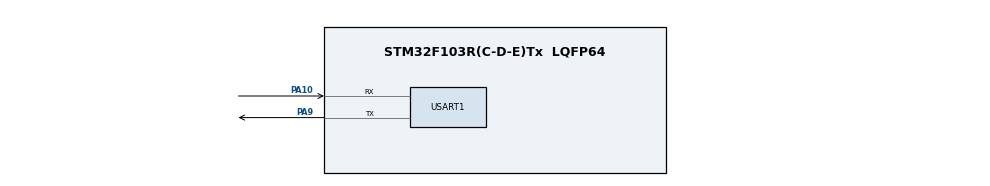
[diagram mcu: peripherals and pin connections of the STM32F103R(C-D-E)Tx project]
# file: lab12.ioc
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FREERTOS.Queues01=myQueue01,16,uint16_t,0,Dynamic,NULL,NULL
FREERTOS.Tasks01=MsgProducer,0,128,MsgProducerTask,Default,NULL,Dynamic,NULL,NULL;MsgConsumer,0,128,MsgConsumerTask,Default,NULL,Dynamic,NULL,NULL
Mcu.Family=STM32F1
Mcu.Name=STM32F103R(C-D-E)Tx
Mcu.Package=LQFP64
NVIC.PriorityGroup=NVIC_PRIORITYGROUP_4
NVIC.TIM3_IRQn=true\:0\:0\:false\:false\:true\:false\:false\:true
NVIC.TimeBase=TIM3_IRQn
NVIC.TimeBaseIP=TIM3
NVIC.USART1_IRQn=true\:0\:0\:false\:false\:true\:false\:true\:true
PA10.Mode=Asynchronous
PA10.Signal=USART1_RX
PA13.Mode=Serial_Wire
PA13.Signal=SYS_JTMS-SWDIO
PA14.Mode=Serial_Wire
PA14.Signal=SYS_JTCK-SWCLK
PA9.Mode=Asynchronous
PA9.Signal=USART1_TX
PD0-OSC_IN.Mode=HSE-External-Oscillator
PD0-OSC_IN.Signal=RCC_OSC_IN
PD1-OSC_OUT.Mode=HSE-External-Oscillator
PD1-OSC_OUT.Signal=RCC_OSC_OUT
ProjectManager.HeapSize=0x200
ProjectManager.StackSize=0x400
ProjectManager.TargetToolchain=STM32CubeIDE
RCC.APB1Freq_Value=8000000
RCC.APB2Freq_Value=8000000
USART1.VirtualMode=VM_ASYNC
VP_FREERTOS_VS_CMSIS_V1.Mode=CMSIS_V1
VP_SYS_VS_tim3.Mode=TIM3
board=custom

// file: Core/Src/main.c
/* USER CODE BEGIN Header */
/**
  ******************************************************************************
  * @file           : main.c
  * @brief          : Main program body
  ******************************************************************************
  * @attention
  *
  * <h2><center>&copy; Copyright (c) 2020 STMicroelectronics.
  * All rights reserved.</center></h2>
  *
  * This software component is licensed by ST under BSD 3-Clause license,
  * the "License"; You may not use this file except in compliance with the
  * License. You may obtain a copy of the License at:
  *                        opensource.org/licenses/BSD-3-Clause
  *
  ******************************************************************************
  */
/* USER CODE END Header */
#include "main.h"
#include "cmsis_os.h"
#include "usart.h"
#include "gpio.h"

void SystemClock_Config(void);
void MX_FREERTOS_Init(void);

int main(void)
{

  /* MCU Configuration--------------------------------------------------------*/

  /* Reset of all peripherals, Initializes the Flash interface and the Systick. */
  HAL_Init();

  /* Configure the system clock */
  SystemClock_Config();

  /* Initialize all configured peripherals */
  MX_GPIO_Init();
  MX_USART1_UART_Init();

  /* Call init function for freertos objects (in freertos.c) */
  MX_FREERTOS_Init();
  /* Start scheduler */
  osKernelStart();

  /* We should never get here as control is now taken by the scheduler */
  /* Infinite loop */
  while (1)
  {

  }
}

void SystemClock_Config(void)
{
  RCC_OscInitTypeDef RCC_OscInitStruct = {0};
  RCC_ClkInitTypeDef RCC_ClkInitStruct = {0};

  /** Initializes the RCC Oscillators according to the specified parameters
  * in the RCC_OscInitTypeDef structure.
  */
  RCC_OscInitStruct.OscillatorType = RCC_OSCILLATORTYPE_HSI;
  RCC_OscInitStruct.HSIState = RCC_HSI_ON;
  RCC_OscInitStruct.HSICalibrationValue = RCC_HSICALIBRATION_DEFAULT;
  RCC_OscInitStruct.PLL.PLLState = RCC_PLL_NONE;
  if (HAL_RCC_OscConfig(&RCC_OscInitStruct) != HAL_OK)
  {
    Error_Handler();
  }
  /** Initializes the CPU, AHB and APB buses clocks
  */
  RCC_ClkInitStruct.ClockType = RCC_CLOCKTYPE_HCLK|RCC_CLOCKTYPE_SYSCLK
                              |RCC_CLOCKTYPE_PCLK1|RCC_CLOCKTYPE_PCLK2;
  RCC_ClkInitStruct.SYSCLKSource = RCC_SYSCLKSOURCE_HSI;
  RCC_ClkInitStruct.AHBCLKDivider = RCC_SYSCLK_DIV1;
  RCC_ClkInitStruct.APB1CLKDivider = RCC_HCLK_DIV1;
  RCC_ClkInitStruct.APB2CLKDivider = RCC_HCLK_DIV1;

  if (HAL_RCC_ClockConfig(&RCC_ClkInitStruct, FLASH_LATENCY_0) != HAL_OK)
  {
    Error_Handler();
  }
}

void HAL_TIM_PeriodElapsedCallback(TIM_HandleTypeDef *htim)
{
  if (htim->Instance == TIM3) {
    HAL_IncTick();
  }
}

void Error_Handler(void)
{
}

/************************ (C) COPYRIGHT STMicroelectronics *****END OF FILE****/

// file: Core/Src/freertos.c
/* USER CODE BEGIN Header */
/**
  ******************************************************************************
  * File Name          : freertos.c
  * Description        : Code for freertos applications
  ******************************************************************************
  * @attention
  *
  * <h2><center>&copy; Copyright (c) 2020 STMicroelectronics.
  * All rights reserved.</center></h2>
  *
  * This software component is licensed by ST under Ultimate Liberty license
  * SLA0044, the "License"; You may not use this file except in compliance with
  * the License. You may obtain a copy of the License at:
  *                             www.st.com/SLA0044
  *
  ******************************************************************************
  */
/* USER CODE END Header */

#include "FreeRTOS.h"
#include "task.h"
#include "main.h"
#include "cmsis_os.h"

/* USER CODE BEGIN Includes */
typedef struct
{
  uint16_t var;
} mailStruct;
osMailQId mail01Handle;
UART_HandleTypeDef huart1;
int buffer = 0;
/* USER CODE END Includes */

osThreadId MsgProducerHandle;
osThreadId MsgConsumerHandle;
osMessageQId myQueue01Handle;

void MsgProducerTask(void const * argument);
void MsgConsumerTask(void const * argument);

void MX_FREERTOS_Init(void); /* (MISRA C 2004 rule 8.1) */

/* GetIdleTaskMemory prototype (linked to static allocation support) */
void vApplicationGetIdleTaskMemory( StaticTask_t **ppxIdleTaskTCBBuffer, StackType_t **ppxIdleTaskStackBuffer, uint32_t *pulIdleTaskStackSize );

/* USER CODE BEGIN GET_IDLE_TASK_MEMORY */
static StaticTask_t xIdleTaskTCBBuffer;
static StackType_t xIdleStack[configMINIMAL_STACK_SIZE];

void vApplicationGetIdleTaskMemory( StaticTask_t **ppxIdleTaskTCBBuffer, StackType_t **ppxIdleTaskStackBuffer, uint32_t *pulIdleTaskStackSize )
{
  *ppxIdleTaskTCBBuffer = &xIdleTaskTCBBuffer;
  *ppxIdleTaskStackBuffer = &xIdleStack[0];
  *pulIdleTaskStackSize = configMINIMAL_STACK_SIZE;
  /* place for user code */
}
/* USER CODE END GET_IDLE_TASK_MEMORY */

void MX_FREERTOS_Init(void) {

  /* Create the queue(s) */
  /* definition and creation of myQueue01 */
  osMessageQDef(myQueue01, 16, uint16_t);
  myQueue01Handle = osMessageCreate(osMessageQ(myQueue01), NULL);

  /* USER CODE BEGIN RTOS_QUEUES */
  /* add queues, ... */
   osMailQDef(mail01, 4, mailStruct);
   mail01Handle = osMailCreate(osMailQ(mail01), NULL);
  /* USER CODE END RTOS_QUEUES */

  /* Create the thread(s) */
  /* definition and creation of MsgProducer */
  osThreadDef(MsgProducer, MsgProducerTask, osPriorityNormal, 0, 128);
  MsgProducerHandle = osThreadCreate(osThread(MsgProducer), NULL);

  /* definition and creation of MsgConsumer */
  osThreadDef(MsgConsumer, MsgConsumerTask, osPriorityNormal, 0, 128);
  MsgConsumerHandle = osThreadCreate(osThread(MsgConsumer), NULL);

}

void MsgProducerTask(void const * argument)
{
  /* USER CODE BEGIN MsgProducerTask */
	mailStruct * mail;
	char msgs[20];
  /* Infinite loop */
  for(;;)
  {

	  mail = (mailStruct *)osMailAlloc(mail01Handle, osWaitForever);
	  if (mail == NULL){
		  continue;
	  }
	  mail->var = buffer+1;
	  osMailPut(mail01Handle, mail);
	  sprintf(msgs, "Produce value: %d\r\n", buffer+1);
	  HAL_UART_Transmit(&huart1, (uint8_t*)msgs, strlen(msgs), HAL_MAX_DELAY);
	  buffer++;
	  osDelay(1000);
  }
  /* USER CODE END MsgProducerTask */
}

void MsgConsumerTask(void const * argument)
{
  /* USER CODE BEGIN MsgConsumerTask */
	osEvent event;
	mailStruct * pMail;
	char msg[20];
  /* Infinite loop */
  for(;;)
  {

	  event = osMailGet(mail01Handle, osWaitForever);
	  if (event.status == osEventMail)
	  {
		  buffer--;
		  pMail = event.value.p;
		  sprintf(msg, "Consume value: %d\r\n", pMail->var);
	      HAL_UART_Transmit(&huart1, (uint8_t*)msg, strlen(msg), HAL_MAX_DELAY);
	      osMailFree(mail01Handle, pMail);
	      osDelay(2000);
	  }
  }
  /* USER CODE END MsgConsumerTask */
}

/************************ (C) COPYRIGHT STMicroelectronics *****END OF FILE****/
